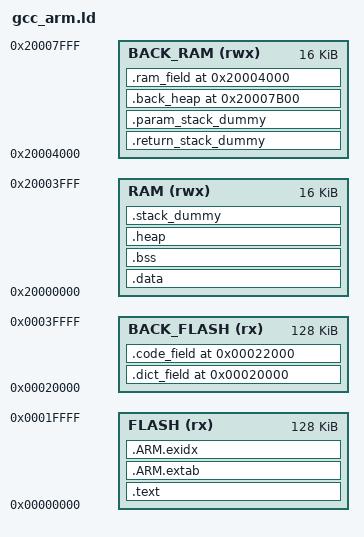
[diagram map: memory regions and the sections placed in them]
/* Linker script to configure memory regions. */
MEMORY
{
  FLASH (rx) : ORIGIN = 0x00000000, LENGTH = 128K
  BACK_FLASH (rx)  : ORIGIN = 0x00020000, LENGTH = 128K  
  RAM (rwx)  : ORIGIN = 0x20000000, LENGTH = 0x04000   /*  16k */
  BACK_RAM (rwx)  : ORIGIN = 0x20004000, LENGTH = 0x04000   /*  16k */  
}

/* Library configurations */
GROUP(libgcc.a libc.a libm.a libnosys.a)

/* Linker script to place sections and symbol values. Should be used together
 * with other linker script that defines memory regions FLASH and RAM.
 * It references following symbols, which must be defined in code:
 *   Reset_Handler : Entry of reset handler
 * 
 * It defines following symbols, which code can use without definition:
 *   __exidx_start
 *   __exidx_end
 *   __etext
 *   __data_start__
 *   __preinit_array_start
 *   __preinit_array_end
 *   __init_array_start
 *   __init_array_end
 *   __fini_array_start
 *   __fini_array_end
 *   __data_end__
 *   __bss_start__
 *   __bss_end__
 *   __end__
 *   end
 *   __HeapLimit
 *   __StackLimit
 *   __StackTop
 *   __stack
 */
ENTRY(Reset_Handler)

SECTIONS
{
	.text :
	{
		KEEP(*(.isr_vector))
		*(.text*)

		KEEP(*(.init))
		KEEP(*(.fini))

		/* .ctors */
		*crtbegin.o(.ctors)
		*crtbegin?.o(.ctors)
		*(EXCLUDE_FILE(*crtend?.o *crtend.o) .ctors)
		*(SORT(.ctors.*))
		*(.ctors)

		/* .dtors */
 		*crtbegin.o(.dtors)
 		*crtbegin?.o(.dtors)
 		*(EXCLUDE_FILE(*crtend?.o *crtend.o) .dtors)
 		*(SORT(.dtors.*))
 		*(.dtors)

		*(.rodata*)

		KEEP(*(.eh_frame*))
	} > FLASH

	.ARM.extab : 
	{
		*(.ARM.extab* .gnu.linkonce.armextab.*)
	} > FLASH

	__exidx_start = .;
	.ARM.exidx :
	{
		*(.ARM.exidx* .gnu.linkonce.armexidx.*)
	} > FLASH
	__exidx_end = .;

	__etext = .;
		
	.data : AT (__etext)
	{
		__data_start__ = .;
		*(vtable)
		*(.data*)

		. = ALIGN(4);
		/* preinit data */
		PROVIDE_HIDDEN (__preinit_array_start = .);
		KEEP(*(.preinit_array))
		PROVIDE_HIDDEN (__preinit_array_end = .);

		. = ALIGN(4);
		/* init data */
		PROVIDE_HIDDEN (__init_array_start = .);
		KEEP(*(SORT(.init_array.*)))
		KEEP(*(.init_array))
		PROVIDE_HIDDEN (__init_array_end = .);


		. = ALIGN(4);
		/* finit data */
		PROVIDE_HIDDEN (__fini_array_start = .);
		KEEP(*(SORT(.fini_array.*)))
		KEEP(*(.fini_array))
		PROVIDE_HIDDEN (__fini_array_end = .);

		. = ALIGN(4);
		/* All data end */
		__data_end__ = .;

	} > RAM

	.bss :
	{
		__bss_start__ = .;
		*(.bss*)
		*(COMMON)
		__bss_end__ = .;
	} > RAM
	
	.heap :
	{
		__end__ = .;
		end = __end__;
		*(.heap*)
		__HeapLimit = .;
	} > RAM

	/* .stack_dummy section doesn't contains any symbols. It is only
	 * used for linker to calculate size of stack sections, and assign
	 * values to stack symbols later */
	.stack_dummy :
	{
		*(.stack)
	} > RAM

	.return_stack_dummy :
	{
		*(.return_stack)
	} > BACK_RAM

	.param_stack_dummy :
	{
		*(.param_stack)
	} > BACK_RAM
    
	.back_heap 0x20007B00:
	{
		*(.back_heap)
	} > BACK_RAM


    .dict_field 0x00020000 :
    {
        KEEP (*(.dict_field))
    } >BACK_FLASH
    .code_field 0x00022000 :
    {
        __code_start__ = .;    
        KEEP (*(.code_field))
    } >BACK_FLASH

    .ram_field 0x20004000 :
    {
        __ram_start__ = .;    
        KEEP (*(.ram_field))
    } >BACK_RAM


	/* Set stack top to end of RAM, and stack limit move down by
	 * size of stack_dummy section */
	__StackTop = ORIGIN(RAM) + LENGTH(RAM);
	__StackLimit = __StackTop - SIZEOF(.stack_dummy);
	PROVIDE(__stack = __StackTop);

	__return_stack_top = ORIGIN(BACK_RAM) + LENGTH(BACK_RAM);
	__return_stack_limit = __return_stack_top - SIZEOF(.return_stack_dummy);
	PROVIDE(__return_stack = __return_stack_top);
    
	__param_stack_top = ORIGIN(BACK_RAM) + LENGTH(BACK_RAM) - SIZEOF(.return_stack_dummy);
	__param_stack_limit = __param_stack_top - SIZEOF(.param_stack_dummy);
	PROVIDE(__param_stack = __param_stack_top);
	
	/* Check if data + heap + stack exceeds RAM limit */
	ASSERT(__StackLimit >= __HeapLimit, "region RAM overflowed with stack")
}
